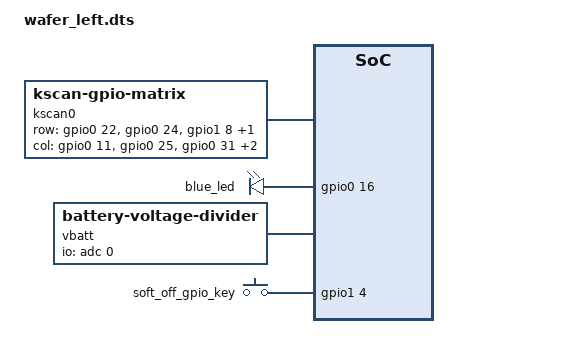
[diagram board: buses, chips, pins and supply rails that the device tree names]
/*
 * SPDX-License-Identifier: MIT
 */

#include "wafer.dtsi"

/ {
    kscan0: kscan {
        compatible = "zmk,kscan-gpio-matrix";
        wakeup-source;
        diode-direction = "col2row";
        row-gpios = <&gpio0 22 (GPIO_ACTIVE_HIGH | GPIO_PULL_DOWN)>,
                    <&gpio0 24 (GPIO_ACTIVE_HIGH | GPIO_PULL_DOWN)>,
                    <&gpio1 8 (GPIO_ACTIVE_HIGH | GPIO_PULL_DOWN)>,
                    <&gpio1 2 (GPIO_ACTIVE_HIGH | GPIO_PULL_DOWN)>;
        col-gpios = <&gpio0 11 GPIO_ACTIVE_HIGH>,
                    <&gpio0 25 GPIO_ACTIVE_HIGH>,
                    <&gpio0 31 GPIO_ACTIVE_HIGH>,
                    <&gpio0 29 GPIO_ACTIVE_HIGH>,
                    <&gpio1 13 GPIO_ACTIVE_HIGH>;
    };

    leds {
        compatible = "gpio-leds";
        blue_led: led_0 {
            gpios = <&gpio0 16 GPIO_ACTIVE_HIGH>;
        };
    };

    vbatt: vbatt {
        compatible = "zmk,battery-voltage-divider";
        io-channels = <&adc 0>;
        output-ohms = <1960000>;
        full-ohms = <(1960000 + 810000)>;
    };

    keys {
        compatible = "gpio-keys";
        soft_off_gpio_key: soft_off_gpio_key {
            gpios = <&gpio1 4 (GPIO_ACTIVE_HIGH | GPIO_PULL_DOWN)>;
        };
    };

    behaviors {
        hw_soft_off: hw_soft_off {
            compatible = "zmk,behavior-soft-off";
            #binding-cells = <0>;
            split-peripheral-off-on-press;
            hold-time-ms = <5000>;
        };
    };

    wakeup_scan: wakeup_scan {
        compatible = "zmk,kscan-gpio-direct";
        input-keys = <&soft_off_gpio_key>;
        wakeup-source;
    };

    side_band_behavior_triggers: side_band_behavior_triggers {
        compatible = "zmk,kscan-sideband-behaviors";
        kscan = <&wakeup_scan>;
        auto-enable;
        wakeup-source;

        soft_off {
            column = <0>;
            row = <0>;
            bindings = <&hw_soft_off>;
        };
    };

    soft_off_wakers {
        compatible = "zmk,soft-off-wakeup-sources";
        wakeup-sources = <&wakeup_scan>;
    };
};
